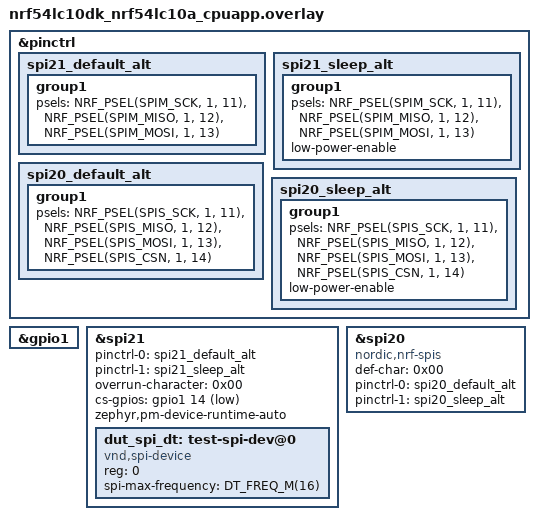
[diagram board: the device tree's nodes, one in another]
/*
 * Copyright (c) 2026 Nordic Semiconductor ASA
 *
 * SPDX-License-Identifier: LicenseRef-Nordic-5-Clause
 */

/* Test requires following loopbacks:
 * SCK:  shared P1.11 (SPIM / SPIS)
 * MISO: shared P1.12
 * MOSI: shared P1.13
 * CS:   SPIM gpio P1.14 to SPIS CSN P1.14
 */

&pinctrl {
	spi21_default_alt: spi21_default_alt {
		group1 {
			psels = <NRF_PSEL(SPIM_SCK, 1, 11)>,
				<NRF_PSEL(SPIM_MISO, 1, 12)>,
				<NRF_PSEL(SPIM_MOSI, 1, 13)>;
		};
	};

	spi21_sleep_alt: spi21_sleep_alt {
		group1 {
			psels = <NRF_PSEL(SPIM_SCK, 1, 11)>,
				<NRF_PSEL(SPIM_MISO, 1, 12)>,
				<NRF_PSEL(SPIM_MOSI, 1, 13)>;
			low-power-enable;
		};
	};

	spi20_default_alt: spi20_default_alt {
		group1 {
			psels = <NRF_PSEL(SPIS_SCK, 1, 11)>,
				<NRF_PSEL(SPIS_MISO, 1, 12)>,
				<NRF_PSEL(SPIS_MOSI, 1, 13)>,
				<NRF_PSEL(SPIS_CSN, 1, 14)>;
		};
	};

	spi20_sleep_alt: spi20_sleep_alt {
		group1 {
			psels = <NRF_PSEL(SPIS_SCK, 1, 11)>,
				<NRF_PSEL(SPIS_MISO, 1, 12)>,
				<NRF_PSEL(SPIS_MOSI, 1, 13)>,
				<NRF_PSEL(SPIS_CSN, 1, 14)>;
			low-power-enable;
		};
	};
};

&gpio1 {
	status = "okay";
};

&spi21 {
	status = "okay";
	pinctrl-0 = <&spi21_default_alt>;
	pinctrl-1 = <&spi21_sleep_alt>;
	pinctrl-names = "default", "sleep";
	overrun-character = <0x00>;
	cs-gpios = <&gpio1 14 GPIO_ACTIVE_LOW>;
	zephyr,pm-device-runtime-auto;

	dut_spi_dt: test-spi-dev@0 {
		compatible = "vnd,spi-device";
		reg = <0>;
		spi-max-frequency = <DT_FREQ_M(16)>;
	};
};

dut_spis: &spi20 {
	compatible = "nordic,nrf-spis";
	status = "okay";
	def-char = <0x00>;
	pinctrl-0 = <&spi20_default_alt>;
	pinctrl-1 = <&spi20_sleep_alt>;
	pinctrl-names = "default", "sleep";
	/delete-property/ rx-delay-supported;
	/delete-property/ rx-delay;
};
